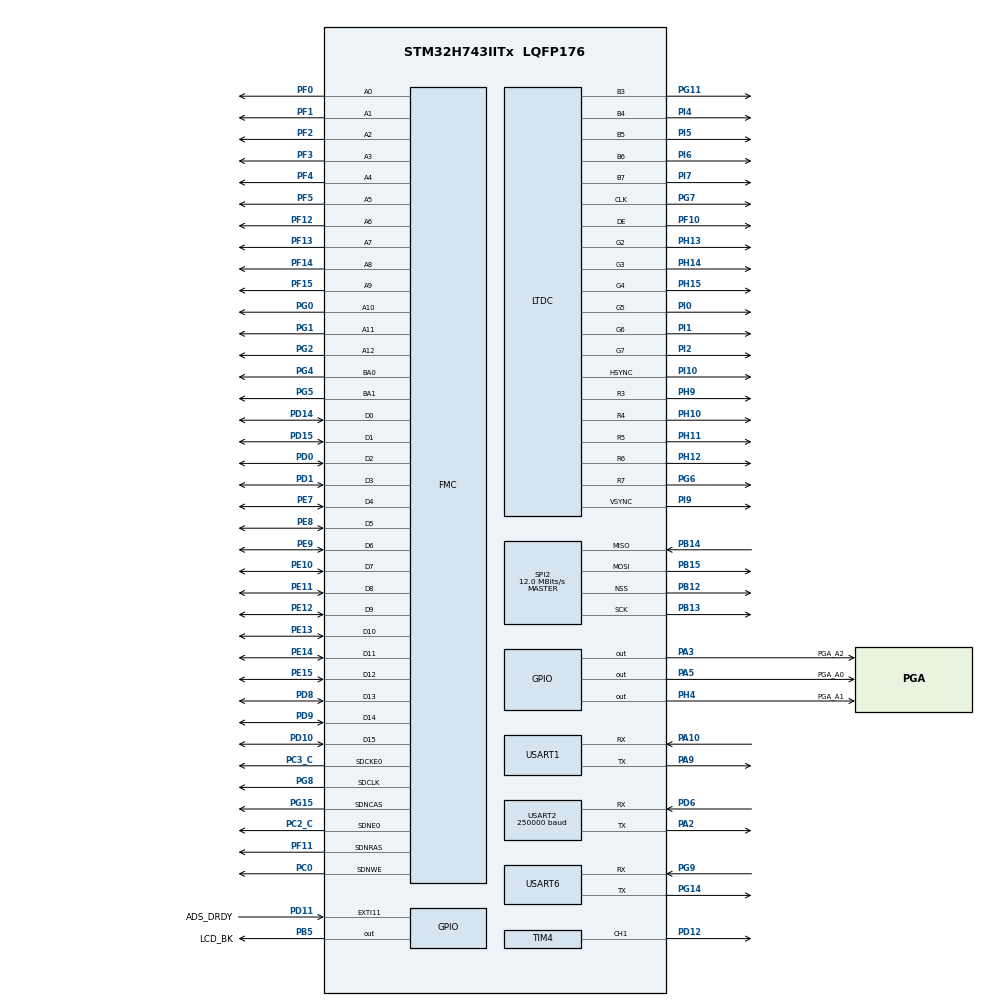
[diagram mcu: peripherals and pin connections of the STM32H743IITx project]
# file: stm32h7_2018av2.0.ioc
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CORTEX_M7.CPU_DCache=Disabled
CORTEX_M7.CPU_ICache=Disabled
CORTEX_M7.MPU_Control=__NULL
CORTEX_M7.default_mode_Activation=1
DMA2D.ColorMode=DMA2D_OUTPUT_RGB565
FMC.CASLatency1=FMC_SDRAM_CAS_LATENCY_3
FMC.ColumnBitsNumber1=FMC_SDRAM_COLUMN_BITS_NUM_9
FMC.ExitSelfRefreshDelay1=9
FMC.LoadToActiveDelay1=2
FMC.RCDDelay1=2
FMC.RPDelay1=2
FMC.ReadBurst1=FMC_SDRAM_RBURST_ENABLE
FMC.ReadPipeDelay1=FMC_SDRAM_RPIPE_DELAY_2
FMC.ReadPipeDelay2=FMC_SDRAM_RPIPE_DELAY_2
FMC.RowCycleDelay1=7
FMC.SDClockPeriod1=FMC_SDRAM_CLOCK_PERIOD_2
FMC.SelfRefreshTime1=6
FMC.WriteRecoveryTime1=5
LTDC.ActiveH=PIXELS_H
LTDC.ActiveW=PIXELS_W
LTDC.Alpha_L0=255
LTDC.Blue=0
LTDC.Blue_L0=0
LTDC.FBStartAdress_L0=0xc0000000
LTDC.Green=0
LTDC.HBP=140
LTDC.HFP=160
LTDC.HSync=20
LTDC.ImageHeight_L0=PIXELS_H
LTDC.ImageWidth_L0=PIXELS_W
LTDC.Layers=0
LTDC.PixelFormat_L0=LTDC_PIXEL_FORMAT_RGB565
LTDC.Red=0
LTDC.VBP=20
LTDC.VFP=12
LTDC.VSync=3
LTDC.WindowX1_L0=PIXELS_W
LTDC.WindowY1_L0=PIXELS_H
Mcu.Family=STM32H7
Mcu.Name=STM32H743IITx
Mcu.Package=LQFP176
Mcu.UserConstants=PIXELS_DIR,1;PIXELS_H,480;PIXELS_W,800;LTDC_BUFF_ADDR,0XC0000000
NVIC.DMA2D_IRQn=true\:0\:0\:false\:false\:true\:true\:true\:true
NVIC.EXTI15_10_IRQn=true\:0\:0\:false\:false\:true\:true\:true\:true
NVIC.PriorityGroup=NVIC_PRIORITYGROUP_4
NVIC.USART1_IRQn=true\:0\:0\:false\:false\:true\:true\:true\:true
PA10.Mode=Asynchronous
PA10.Signal=USART1_RX
PA2.Mode=Asynchronous
PA2.Signal=USART2_TX
PA3.GPIO_Label=PGA_A2
PA3.GPIO_PuPd=GPIO_PULLDOWN
PA3.PinState=GPIO_PIN_RESET
PA3.Signal=GPIO_Output
PA5.GPIO_Label=PGA_A0
PA5.GPIO_PuPd=GPIO_PULLDOWN
PA5.Signal=GPIO_Output
PA9.Mode=Asynchronous
PA9.Signal=USART1_TX
PB12.Mode=NSS_Signal_Hard_Output
PB12.Signal=SPI2_NSS
PB13.Mode=Full_Duplex_Master
PB13.Signal=SPI2_SCK
PB14.GPIO_PuPd=GPIO_PULLDOWN
PB14.Mode=Full_Duplex_Master
PB14.Signal=SPI2_MISO
PB15.Mode=Full_Duplex_Master
PB15.Signal=SPI2_MOSI
PB5.GPIO_Label=LCD_BK
PB5.GPIO_PuPd=GPIO_PULLDOWN
PB5.Signal=GPIO_Output
PB9.Signal=S_TIM4_CH4
PC0.Signal=FMC_SDNWE
PC1.Signal=ADCx_INP11
PC14-OSC32_IN\ (OSC32_IN).Mode=LSE-External-Oscillator
PC14-OSC32_IN\ (OSC32_IN).Signal=RCC_OSC32_IN
PC15-OSC32_OUT\ (OSC32_OUT).Mode=LSE-External-Oscillator
PC15-OSC32_OUT\ (OSC32_OUT).Signal=RCC_OSC32_OUT
PC2_C.Mode=SdramChipSelect1_1
PC2_C.Signal=FMC_SDNE0
PC3_C.Mode=SdramChipSelect1_1
PC3_C.Signal=FMC_SDCKE0
PD0.Signal=FMC_D2_DA2
PD1.Signal=FMC_D3_DA3
PD10.Signal=FMC_D15_DA15
PD11.GPIO_Label=ADS_DRDY
PD11.GPIO_ModeDefaultEXTI=GPIO_MODE_IT_FALLING
PD11.Signal=GPXTI11
PD12.Signal=S_TIM4_CH1
PD14.Signal=FMC_D0_DA0
PD15.Signal=FMC_D1_DA1
PD6.Mode=Asynchronous
PD6.Signal=USART2_RX
PD8.Signal=FMC_D13_DA13
PD9.Signal=FMC_D14_DA14
PE0.Signal=FMC_NBL0
PE1.Signal=FMC_NBL1
PE10.Signal=FMC_D7_DA7
PE11.Signal=FMC_D8_DA8
PE12.Signal=FMC_D9_DA9
PE13.Signal=FMC_D10_DA10
PE14.Signal=FMC_D11_DA11
PE15.Signal=FMC_D12_DA12
PE7.Signal=FMC_D4_DA4
PE8.Signal=FMC_D5_DA5
PE9.Signal=FMC_D6_DA6
PF0.Signal=FMC_A0
PF1.Signal=FMC_A1
PF10.GPIO_Speed=GPIO_SPEED_FREQ_VERY_HIGH
PF10.Mode=RGB565
PF10.Signal=LTDC_DE
PF11.Signal=FMC_SDNRAS
PF12.Signal=FMC_A6
PF13.Signal=FMC_A7
PF14.Signal=FMC_A8
PF15.Signal=FMC_A9
PF2.Signal=FMC_A2
PF3.Signal=FMC_A3
PF4.Signal=FMC_A4
PF5.Signal=FMC_A5
PG0.Signal=FMC_A10
PG1.Signal=FMC_A11
PG11.GPIO_Speed=GPIO_SPEED_FREQ_VERY_HIGH
PG11.Mode=RGB565
PG11.Signal=LTDC_B3
PG14.Mode=Asynchronous
PG14.Signal=USART6_TX
PG15.Signal=FMC_SDNCAS
PG2.Signal=FMC_A12
PG4.Signal=FMC_A14_BA0
PG5.Signal=FMC_A15_BA1
PG6.GPIO_Speed=GPIO_SPEED_FREQ_VERY_HIGH
PG6.Mode=RGB565
PG6.Signal=LTDC_R7
PG7.GPIO_Speed=GPIO_SPEED_FREQ_VERY_HIGH
PG7.Mode=RGB565
PG7.Signal=LTDC_CLK
PG8.Signal=FMC_SDCLK
PG9.Mode=Asynchronous
PG9.Signal=USART6_RX
PH0-OSC_IN\ (PH0).Mode=HSE-External-Oscillator
PH0-OSC_IN\ (PH0).Signal=RCC_OSC_IN
PH1-OSC_OUT\ (PH1).Mode=HSE-External-Oscillator
PH1-OSC_OUT\ (PH1).Signal=RCC_OSC_OUT
PH10.GPIO_Speed=GPIO_SPEED_FREQ_VERY_HIGH
PH10.Mode=RGB565
PH10.Signal=LTDC_R4
PH11.GPIO_Speed=GPIO_SPEED_FREQ_VERY_HIGH
PH11.Mode=RGB565
PH11.Signal=LTDC_R5
PH12.GPIO_Speed=GPIO_SPEED_FREQ_VERY_HIGH
PH12.Mode=RGB565
PH12.Signal=LTDC_R6
PH13.GPIO_Speed=GPIO_SPEED_FREQ_VERY_HIGH
PH13.Mode=RGB565
PH13.Signal=LTDC_G2
PH14.GPIO_Speed=GPIO_SPEED_FREQ_VERY_HIGH
PH14.Mode=RGB565
PH14.Signal=LTDC_G3
PH15.GPIO_Speed=GPIO_SPEED_FREQ_VERY_HIGH
PH15.Mode=RGB565
PH15.Signal=LTDC_G4
PH4.GPIO_Label=PGA_A1
PH4.GPIO_PuPd=GPIO_PULLDOWN
PH4.Signal=GPIO_Output
PH9.GPIO_Speed=GPIO_SPEED_FREQ_VERY_HIGH
PH9.Mode=RGB565
PH9.Signal=LTDC_R3
PI0.GPIO_Speed=GPIO_SPEED_FREQ_VERY_HIGH
PI0.Mode=RGB565
PI0.Signal=LTDC_G5
PI1.GPIO_Speed=GPIO_SPEED_FREQ_VERY_HIGH
PI1.Mode=RGB565
PI1.Signal=LTDC_G6
PI10.GPIO_Speed=GPIO_SPEED_FREQ_VERY_HIGH
PI10.Mode=RGB565
PI10.Signal=LTDC_HSYNC
PI2.GPIO_Speed=GPIO_SPEED_FREQ_VERY_HIGH
PI2.Mode=RGB565
PI2.Signal=LTDC_G7
PI4.GPIO_Speed=GPIO_SPEED_FREQ_VERY_HIGH
PI4.Mode=RGB565
PI4.Signal=LTDC_B4
PI5.GPIO_Speed=GPIO_SPEED_FREQ_VERY_HIGH
PI5.Mode=RGB565
PI5.Signal=LTDC_B5
PI6.GPIO_Speed=GPIO_SPEED_FREQ_VERY_HIGH
PI6.Mode=RGB565
PI6.Signal=LTDC_B6
PI7.GPIO_Speed=GPIO_SPEED_FREQ_VERY_HIGH
PI7.Mode=RGB565
PI7.Signal=LTDC_B7
PI9.GPIO_Speed=GPIO_SPEED_FREQ_VERY_HIGH
PI9.Mode=RGB565
PI9.Signal=LTDC_VSYNC
ProjectManager.HeapSize=0x16000
ProjectManager.StackSize=0x1000
ProjectManager.TargetToolchain=STM32CubeIDE
RCC.ADCFreq_Value=72000000
RCC.APB1Freq_Value=120000000
RCC.APB2Freq_Value=120000000
RCC.APB3Freq_Value=120000000
RCC.APB4Freq_Value=120000000
RCC.CKPERSourceSelection=RCC_CLKPSOURCE_HSE
RCC.CortexFreq_Value=480000000
RCC.D1PPRE=RCC_APB3_DIV2
RCC.D2PPRE1=RCC_APB1_DIV2
RCC.D2PPRE2=RCC_APB2_DIV2
RCC.D3PPRE=RCC_APB4_DIV2
RCC.DIVM1=5
RCC.DIVM2=5
RCC.DIVM3=1
RCC.DIVN1=192
RCC.DIVN2=72
RCC.DIVN3=9
RCC.DIVP2=5
RCC.DIVQ1=20
RCC.DIVR3=5
RCC.HCLKFreq_Value=240000000
RCC.HPRE=RCC_HCLK_DIV2
RCC.PLL2FRACN=0
RCC.PLL3FRACN=0
RCC.PLLFRACN=0
RCC.PLLSourceVirtual=RCC_PLLSOURCE_HSE
RCC.PWR_Regulator_Voltage_Scale=PWR_REGULATOR_VOLTAGE_SCALE0
RCC.SYSCLKFreq_VALUE=480000000
RCC.SYSCLKSource=RCC_SYSCLKSOURCE_PLLCLK
RCC.USBFreq_Value=48000000
SH.ADCx_INP11.0=ADC1_INP11
SH.FMC_A0.0=FMC_A0,13b-sda1
SH.FMC_A1.0=FMC_A1,13b-sda1
SH.FMC_A10.0=FMC_A10,13b-sda1
SH.FMC_A11.0=FMC_A11,13b-sda1
SH.FMC_A12.0=FMC_A12,13b-sda1
SH.FMC_A14_BA0.0=FMC_BA0,FourSdramBanks1
SH.FMC_A15_BA1.0=FMC_BA1,FourSdramBanks1
SH.FMC_A2.0=FMC_A2,13b-sda1
SH.FMC_A3.0=FMC_A3,13b-sda1
SH.FMC_A4.0=FMC_A4,13b-sda1
SH.FMC_A5.0=FMC_A5,13b-sda1
SH.FMC_A6.0=FMC_A6,13b-sda1
SH.FMC_A7.0=FMC_A7,13b-sda1
SH.FMC_A8.0=FMC_A8,13b-sda1
SH.FMC_A9.0=FMC_A9,13b-sda1
SH.FMC_D0_DA0.0=FMC_D0,sd-16b-d1
SH.FMC_D10_DA10.0=FMC_D10,sd-16b-d1
SH.FMC_D11_DA11.0=FMC_D11,sd-16b-d1
SH.FMC_D12_DA12.0=FMC_D12,sd-16b-d1
SH.FMC_D13_DA13.0=FMC_D13,sd-16b-d1
SH.FMC_D14_DA14.0=FMC_D14,sd-16b-d1
SH.FMC_D15_DA15.0=FMC_D15,sd-16b-d1
SH.FMC_D1_DA1.0=FMC_D1,sd-16b-d1
SH.FMC_D2_DA2.0=FMC_D2,sd-16b-d1
SH.FMC_D3_DA3.0=FMC_D3,sd-16b-d1
SH.FMC_D4_DA4.0=FMC_D4,sd-16b-d1
SH.FMC_D5_DA5.0=FMC_D5,sd-16b-d1
SH.FMC_D6_DA6.0=FMC_D6,sd-16b-d1
SH.FMC_D7_DA7.0=FMC_D7,sd-16b-d1
SH.FMC_D8_DA8.0=FMC_D8,sd-16b-d1
SH.FMC_D9_DA9.0=FMC_D9,sd-16b-d1
SH.FMC_NBL0.0=FMC_NBL0
SH.FMC_NBL1.0=FMC_NBL1
SH.FMC_SDCLK.0=FMC_SDCLK,13b-sda1
SH.FMC_SDNCAS.0=FMC_SDNCAS,13b-sda1
SH.FMC_SDNRAS.0=FMC_SDNRAS,13b-sda1
SH.FMC_SDNWE.0=FMC_SDNWE,13b-sda1
SH.S_TIM4_CH1.0=TIM4_CH1,PWM Generation1 CH1
SH.S_TIM4_CH4.0=TIM4_CH4
SPI2.BaudRatePrescaler=SPI_BAUDRATEPRESCALER_4
SPI2.CLKPhase=SPI_PHASE_2EDGE
SPI2.CalculateBaudRate=12.0 MBits/s
SPI2.DataSize=SPI_DATASIZE_32BIT
SPI2.Direction=SPI_DIRECTION_2LINES
SPI2.Mode=SPI_MODE_MASTER
SPI2.VirtualNSS=VM_NSSHARD
SPI2.VirtualType=VM_MASTER
STMicroelectronics.X-CUBE-ALGOBUILD.1.3.0.LibraryCcDSPOoLibraryJjDSPOoLibrary=true
TIM4.AutoReloadPreload=TIM_AUTORELOAD_PRELOAD_ENABLE
TIM4.Channel-PWM\ Generation1\ CH1=TIM_CHANNEL_1
TIM4.Period=15-1
TIM4.Prescaler=1-1
TIM4.Pulse-PWM\ Generation1\ CH1=8
TIM4.TIM_MasterOutputTrigger=TIM_TRGO_UPDATE
USART1.VirtualMode-Asynchronous=VM_ASYNC
USART2.BaudRate=250000
USART2.VirtualMode-Asynchronous=VM_ASYNC
USART6.VirtualMode-Asynchronous=VM_ASYNC
VP_DMA2D_VS_DMA2D.Mode=DMA2D_Activate
VP_STMicroelectronics.X-CUBE-ALGOBUILD_VS_DSPOoLibraryJjLibrary_1.3.0_1.3.0.Mode=DSPOoLibraryJjLibrary
VP_TIM4_VS_ClockSourceINT.Mode=Internal
board=custom

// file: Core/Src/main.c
/* USER CODE BEGIN Header */
/**
  ******************************************************************************
  * @file           : main.c
  * @brief          : Main program body
  ******************************************************************************
  * @attention
  *
  * Copyright (c) 2023 STMicroelectronics.
  * All rights reserved.
  *
  * This software is licensed under terms that can be found in the LICENSE file
  * in the root directory of this software component.
  * If no LICENSE file comes with this software, it is provided AS-IS.
  *
  ******************************************************************************
  */
/* USER CODE END Header */
#include "main.h"
#include "dma2d.h"
#include "ltdc.h"
#include "spi.h"
#include "tim.h"
#include "usart.h"
#include "gpio.h"
#include "fmc.h"

/* USER CODE BEGIN Includes */
#include "stdio.h"
#include "lvgl.h"
#include "lv_port_disp.h"
#include "lv_port_indev.h"
#include "ui.h"
//#include "correct.h"
#include "arm_math.h"
//#include "dsp_app.h"
#include "ads_app.h"
#include "my_dsp.h"
#include "ad9959_uart.h"
#include "module_port.h"
/* USER CODE END Includes */

/* USER CODE BEGIN PV */

//static uint16_t adc1_buffer[ADC_LENGTH];
//static uint16_t adc3_buffer[ADC_LENGTH];
//static uint8_t ADC3_DONE=0;
/* USER CODE END PV */

void SystemClock_Config(void);

int main(void)
{

  /* MCU Configuration--------------------------------------------------------*/

  /* Reset of all peripherals, Initializes the Flash interface and the Systick. */
  HAL_Init();

  /* Configure the system clock */
  SystemClock_Config();

  /* Initialize all configured peripherals */
  MX_GPIO_Init();
  MX_FMC_Init();
  MX_USART1_UART_Init();
  MX_DMA2D_Init();
  MX_LTDC_Init();
  MX_USART2_UART_Init();
  MX_SPI2_Init();
  MX_TIM4_Init();
  MX_USART6_UART_Init();
  /* USER CODE BEGIN 2 */
  /*---RGB SCREEN INIT---*/
//    DSP_ex1();
printf("程序开始\n\r");
    app_dsp_init();
    SDRAM_InitSequence();
    lv_init();
    lv_port_disp_init();
    lv_port_indev_init();
    ui_init();
//    draw_smith_Demo();
//    ADS131A04_Init();

//    AD9959_init();
//    AD9959_setFreq(0,1000000);
  /*---TIME AND ADC---*/
//    dsp_init();

  /* USER CODE END 2 */

  /* Infinite loop */
  /* USER CODE BEGIN WHILE */
  while (1)
  {

      sweep_task();
//      measure_task();

    /* USER CODE END WHILE */

  }
}

void SystemClock_Config(void)
{
  RCC_OscInitTypeDef RCC_OscInitStruct = {0};
  RCC_ClkInitTypeDef RCC_ClkInitStruct = {0};

  /** Supply configuration update enable
  */
  HAL_PWREx_ConfigSupply(PWR_LDO_SUPPLY);

  /** Configure the main internal regulator output voltage
  */
  __HAL_PWR_VOLTAGESCALING_CONFIG(PWR_REGULATOR_VOLTAGE_SCALE1);

  while(!__HAL_PWR_GET_FLAG(PWR_FLAG_VOSRDY)) {}

  __HAL_RCC_SYSCFG_CLK_ENABLE();
  __HAL_PWR_VOLTAGESCALING_CONFIG(PWR_REGULATOR_VOLTAGE_SCALE0);

  while(!__HAL_PWR_GET_FLAG(PWR_FLAG_VOSRDY)) {}

  /** Macro to configure the PLL clock source
  */
  __HAL_RCC_PLL_PLLSOURCE_CONFIG(RCC_PLLSOURCE_HSE);

  /** Initializes the RCC Oscillators according to the specified parameters
  * in the RCC_OscInitTypeDef structure.
  */
  RCC_OscInitStruct.OscillatorType = RCC_OSCILLATORTYPE_HSE;
  RCC_OscInitStruct.HSEState = RCC_HSE_ON;
  RCC_OscInitStruct.PLL.PLLState = RCC_PLL_ON;
  RCC_OscInitStruct.PLL.PLLSource = RCC_PLLSOURCE_HSE;
  RCC_OscInitStruct.PLL.PLLM = 5;
  RCC_OscInitStruct.PLL.PLLN = 192;
  RCC_OscInitStruct.PLL.PLLP = 2;
  RCC_OscInitStruct.PLL.PLLQ = 20;
  RCC_OscInitStruct.PLL.PLLR = 2;
  RCC_OscInitStruct.PLL.PLLRGE = RCC_PLL1VCIRANGE_2;
  RCC_OscInitStruct.PLL.PLLVCOSEL = RCC_PLL1VCOWIDE;
  RCC_OscInitStruct.PLL.PLLFRACN = 0;
  if (HAL_RCC_OscConfig(&RCC_OscInitStruct) != HAL_OK)
  {
    Error_Handler();
  }

  /** Initializes the CPU, AHB and APB buses clocks
  */
  RCC_ClkInitStruct.ClockType = RCC_CLOCKTYPE_HCLK|RCC_CLOCKTYPE_SYSCLK
                              |RCC_CLOCKTYPE_PCLK1|RCC_CLOCKTYPE_PCLK2
                              |RCC_CLOCKTYPE_D3PCLK1|RCC_CLOCKTYPE_D1PCLK1;
  RCC_ClkInitStruct.SYSCLKSource = RCC_SYSCLKSOURCE_PLLCLK;
  RCC_ClkInitStruct.SYSCLKDivider = RCC_SYSCLK_DIV1;
  RCC_ClkInitStruct.AHBCLKDivider = RCC_HCLK_DIV2;
  RCC_ClkInitStruct.APB3CLKDivider = RCC_APB3_DIV2;
  RCC_ClkInitStruct.APB1CLKDivider = RCC_APB1_DIV2;
  RCC_ClkInitStruct.APB2CLKDivider = RCC_APB2_DIV2;
  RCC_ClkInitStruct.APB4CLKDivider = RCC_APB4_DIV2;

  if (HAL_RCC_ClockConfig(&RCC_ClkInitStruct, FLASH_LATENCY_4) != HAL_OK)
  {
    Error_Handler();
  }
}

void Error_Handler(void)
{
  __disable_irq();
  while (1)
  {
  }
}
